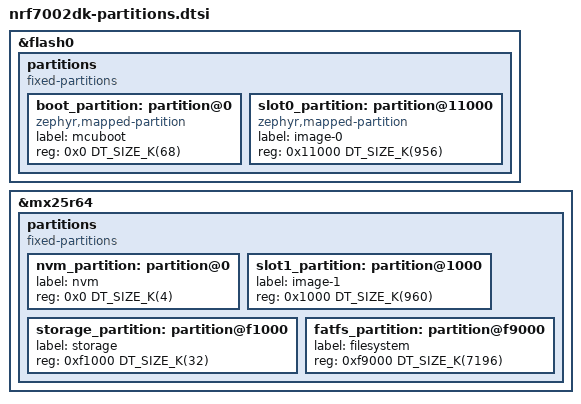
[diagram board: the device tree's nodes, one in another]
/* Partition layout for nrf7002dk: the flash memory map shared by the
 * bootloader and every application image. Generated by
 * tools/partition_layout.py; do not edit by hand -- re-run
 * `python3 tools/partition_layout.py --fix nrf7002dk` after changing
 * the upstream board geometry or tools/boards.toml.
 *
 * Board-specific overlay glue (delete-nodes, device enablement,
 * aliases/chosen) lives in dts/nordic/nrf7002dk.dtsi, which includes
 * this file.
 */

&flash0 {
	partitions {
		compatible = "fixed-partitions";
		#address-cells = <1>;
		#size-cells = <1>;
		ranges;

		boot_partition: partition@0 {
			compatible = "zephyr,mapped-partition";
			label = "mcuboot";
			reg = <0x0 DT_SIZE_K(68)>;
		};

		slot0_partition: partition@11000 {
			compatible = "zephyr,mapped-partition";
			label = "image-0";
			reg = <0x11000 DT_SIZE_K(956)>;
		};
	};
};

&mx25r64 {
	partitions {
		compatible = "fixed-partitions";
		#address-cells = <1>;
		#size-cells = <1>;

		nvm_partition: partition@0 {
			label = "nvm";
			reg = <0x0 DT_SIZE_K(4)>;
		};

		slot1_partition: partition@1000 {
			label = "image-1";
			reg = <0x1000 DT_SIZE_K(960)>;
		};

		storage_partition: partition@f1000 {
			label = "storage";
			reg = <0xf1000 DT_SIZE_K(32)>;
		};

		fatfs_partition: partition@f9000 {
			label = "filesystem";
			reg = <0xf9000 DT_SIZE_K(7196)>;
		};
	};
};
